# nrf9120_mlm1_modem register map
Vendor: Nordic Semiconductor; Series: nrf91; File version: 1
CPU: CM4 r0p1, little endian, MPU, no FPU, 3 interrupt priority bits
Registers are 32-bit, read-write, reset 0x0 unless marked. A register's access mark holds for its fields unless they carry their own. Offsets are from the block's base; [hi:lo] are bit positions; {n}, {i} and the like mark numbered series.

## MODEMPERIPH — Modem peripheral registers
Base 0x40021000
Same registers: L2CIPHER 0x40040000
0x70 TASKZEROPENALTY_PCP_1 wo — TaskZeroPenalty register for PCP 1
  [0] ZERO_PENALTY
    1=SET_ZERO_PENALTY
0x74 TASKFULLPENALTY_PCP_1 wo — TaskFullPenalty register for PCP 1
  [0] FULL_PENALTY
    1=SET_FULL_PENALTY
0x78 TASKZEROPENALTY_PCP_0 wo — TaskZeroPenalty register for PCP 0
  [0] ZERO_PENALTY
    1=SET_ZERO_PENALTY
0x7C TASKFULLPENALTY_PCP_0 wo — TaskFullPenalty register for PCP 0
  [0] FULL_PENALTY
    1=SET_FULL_PENALTY
{0xC00+4i} PENALTY_REG[{i}] (i=0..1) — Description collection: Penalty register for PCP n
  [1:0] Penalty — Penalty Level
    0=Full (Auto 0) Full penalty)); 1=Semi1 ((Auto 1) Semi (power on, clock off)); 2=Semi0 ((Auto 2) Semi (power on, clock core on, clock buffer off)); 3=Zero ((Auto 3) Zero penalty)
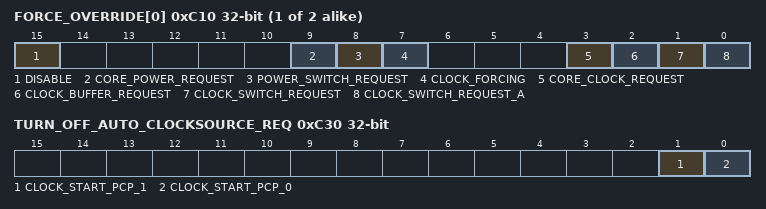
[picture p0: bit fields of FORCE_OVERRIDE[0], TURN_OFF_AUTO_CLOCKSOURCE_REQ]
{0xC10+4i} FORCE_OVERRIDE[{i}] (i=0..1) — Description collection: Force override register for PCP n
  [15] DISABLE
    0=DISABLE (all forcing disabled); 1=ENABLE (all forcing enabled)
  [9] CORE_POWER_REQUEST
    0=REQ0 (powerRequest.core = 0); 1=REQ1 (powerRequest.core = 1)
  [8] POWER_SWITCH_REQUEST
    0=REQ0 (powerRequest.switch = 0); 1=REQ1 (powerRequest.switch = 1)
  [7] CLOCK_FORCING
    0=FORCE0 (All clock forcing disabled); 1=FORCE1 (All clock forcing enabled)
  [3] CORE_CLOCK_REQUEST
    0=REQ0 (clockRequest.core = 0); 1=REQ1 (clockRequest.core = 1)
  [2] CLOCK_BUFFER_REQUEST
    0=REQ0 (clockRequest.buff = 0); 1=REQ1 (clockRequest.buff = 1)
  [1] CLOCK_SWITCH_REQUEST
    0=REQ0 (clockRequest.switch = 0); 1=REQ1 (clockRequest.switch = 1)
  [0] CLOCK_SWITCH_REQUEST_A
    0=REQ0 (clockRequest.switch_a = 0); 1=REQ1 (clockRequest.switch_a = 1)
0xC30 TURN_OFF_AUTO_CLOCKSOURCE_REQ — Turn of the automatic clock request.
  [1] CLOCK_START_PCP_1
    0=NORMAL_PCP_1 (normal clock start for PCP 1); 1=OFF_PCP_1 (turn off normal clock start for PCP 1)
  [0] CLOCK_START_PCP_0
    0=NORMAL_PCP_0 (normal clock start for PCP 0); 1=OFF_PCP_0 (turn off normal clock start for PCP 0)

## MODEMTIMER0 — Modem Timer/Counter 0
Base 0x40024000
Same registers: MODEMTIMER1 0x40025000
0x00 TASKS_START wo — Start Timer
  [0] TASKS_START
    1=Trigger task
0x04 TASKS_STOP wo — Stop Timer
  [0] TASKS_STOP
    1=Trigger task
0x08 TASKS_CLEAR wo — Clear time
  [0] TASKS_CLEAR
    1=Trigger task
0x0C TASKS_SHUTDOWN wo — Shut down timer
  [0] TASKS_SHUTDOWN
    1=Trigger task
{0x40+4i} TASKS_CAPTURE[{i}] (i=0..7) wo — Description collection: Capture Timer value to CC[n] register
  [0] TASKS_CAPTURE — Capture Timer value to CC[n] register
    1=Trigger task
{0x100+4i} EVENTS_COMPARE[{i}] (i=0..7) — Description collection: Compare event on CC[n] match.
  [0] EVENTS_COMPARE — Compare event on CC[n] match.
    0=NotGenerated (Event not generated); 1=Generated (Event generated)
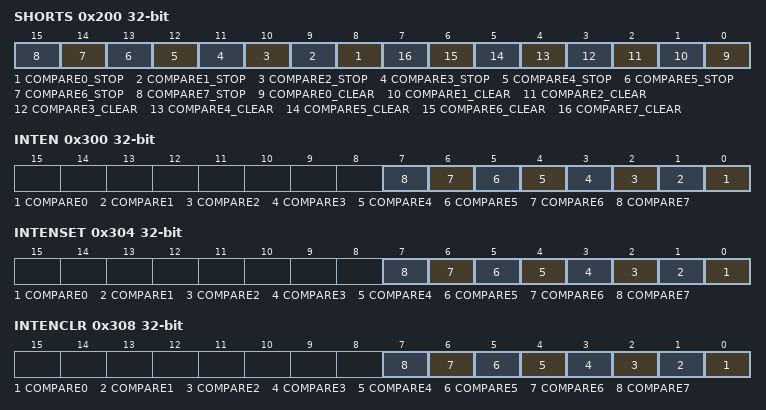
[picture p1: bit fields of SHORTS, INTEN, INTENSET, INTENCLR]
0x200 SHORTS — Shortcuts between local events and tasks
  [all] fields
    0=Disabled (Disable shortcut); 1=Enabled (Enable shortcut)
  [n+8] COMPARE{n}_STOP (n=0..7) — Shortcut between event COMPARE[{n}] and task STOP
  [n] COMPARE{n}_CLEAR (n=0..7) — Shortcut between event COMPARE[{n}] and task CLEAR
0x300 INTEN — Enable or disable interrupt
  [all] fields
    0=Disabled; 1=Enabled
  [n] COMPARE{n} (n=0..7) — Enable or disable interrupt for event COMPARE[{n}]
0x304 INTENSET — Enable interrupt
  [all] fields
    on read: 0=Disabled (Read: Disabled); 1=Enabled (Read: Enabled) | on write: 1=Set (Enable)
  [n] COMPARE{n} (n=0..7) — Write '1' to enable interrupt for event COMPARE[{n}]
0x308 INTENCLR — Disable interrupt
  [all] fields
    on read: 0=Disabled (Read: Disabled); 1=Enabled (Read: Enabled) | on write: 1=Clear (Disable)
  [n] COMPARE{n} (n=0..7) — Write '1' to disable interrupt for event COMPARE[{n}]
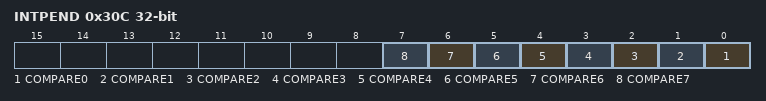
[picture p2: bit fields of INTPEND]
0x30C INTPEND ro — Pending interrupts
  [all] fields
    on read: 0=NotPending (Read: Not pending); 1=Pending (Read: Pending)
  [n] COMPARE{n} (n=0..7) — Read pending status of interrupt for event COMPARE[{n}]
0x504 RUNNING — Status of running timer
  [1:0] STATUS — Current status
    0=SHUTDOWN (Timer is powered off.); 1=RUNNING (Timer is actively running.); 2=STOPPED (Timer is stopped.)
{0x540+8i} CCLO{i} (i=0..7) — Capture/Compare register {i} - Low Word
  [31:0] CCLO — Capture/Compare value Low Word
{0x544+8i} CCHI{i} (i=0..7) — Capture/Compare register {i} - High Word
  [31:0] CCHI — Capture/Compare value High Word
0x580 COUNTLO — Internal Counter Value - Low Word
0x584 COUNTHI — Internal Counter Value - High Word
  [31:0] COUNTHI — Internal Counter Value High Word
0xFFC POWER reset 0x1 — Peripheral power control
  [0] POWER — Peripheral power control. The peripheral and its registers will be reset to its initial state by switching the peripheral off and then back on again.
    0=Disabled (Peripheral is powered off); 1=Enabled (Peripheral is powered on)
